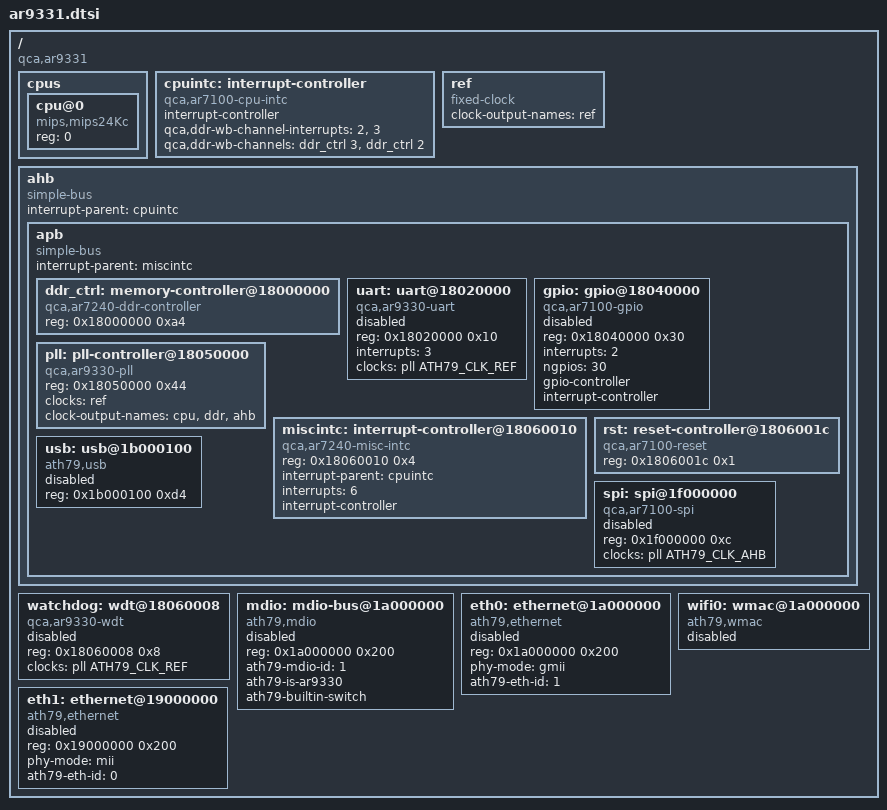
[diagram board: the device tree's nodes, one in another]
#include <dt-bindings/clock/ath79-clk.h>

/ {
	compatible = "qca,ar9331";

	#address-cells = <1>;
	#size-cells = <1>;

	cpus {
		#address-cells = <1>;
		#size-cells = <0>;

		cpu@0 {
			device_type = "cpu";
			compatible = "mips,mips24Kc";
			reg = <0>;
		};
	};

	cpuintc: interrupt-controller {
		compatible = "qca,ar7100-cpu-intc";

		interrupt-controller;
		#interrupt-cells = <1>;

		qca,ddr-wb-channel-interrupts = <2>, <3>;
		qca,ddr-wb-channels = <&ddr_ctrl 3>, <&ddr_ctrl 2>;
	};

	ref: ref {
		compatible = "fixed-clock";
		#clock-cells = <0>;
		clock-output-names = "ref";
	};

	ahb {
		compatible = "simple-bus";
		ranges;

		#address-cells = <1>;
		#size-cells = <1>;

		interrupt-parent = <&cpuintc>;

		apb {
			compatible = "simple-bus";
			ranges;

			#address-cells = <1>;
			#size-cells = <1>;

			interrupt-parent = <&miscintc>;

			ddr_ctrl: memory-controller@18000000 {
				compatible = "qca,ar7240-ddr-controller";
				reg = <0x18000000 0xa4>;

				#qca,ddr-wb-channel-cells = <1>;
			};

			uart: uart@18020000 {
				compatible = "qca,ar9330-uart";
				reg = <0x18020000 0x10>;

				interrupts = <3>;

				clocks = <&pll ATH79_CLK_REF>;
				clock-names = "uart";

				status = "disabled";
			};

			gpio: gpio@18040000 {
				compatible = "qca,ar7100-gpio";
				reg = <0x18040000 0x30>;
				interrupts = <2>;

				ngpios = <30>;

				gpio-controller;
				#gpio-cells = <2>;

				interrupt-controller;
				#interrupt-cells = <2>;

				status = "disabled";
			};

			pll: pll-controller@18050000 {
				compatible = "qca,ar9330-pll";
				reg = <0x18050000 0x44>;

				clocks = <&ref>;
				clock-names = "ref";

				#clock-cells = <1>;
				clock-output-names = "cpu", "ddr", "ahb";
			};

			miscintc: interrupt-controller@18060010 {
				compatible = "qca,ar7240-misc-intc";
				reg = <0x18060010 0x4>;

				interrupt-parent = <&cpuintc>;
				interrupts = <6>;

				interrupt-controller;
				#interrupt-cells = <1>;
			};

			rst: reset-controller@1806001c {
				compatible = "qca,ar7100-reset";
				reg = <0x1806001c 0x1>;

				#reset-cells = <1>;
			};

			usb: usb@1b000100 {
			/*	compatible = "qca,ar7100-ehci", "generic-ehci";
				reg = <0x1b000100 0xd4>;

				interrupt-parent = <&cpuintc>;
				interrupts = <3>;
				resets = <&rst 5>;

				has-transaction-translator;

				phy-names = "usb";
				phys = <&usb_phy>;*/

				compatible = "ath79,usb";
				reg = <0x1b000100 0xd4>;

				status = "disabled";
			};

			spi: spi@1f000000 {
				compatible = "qca,ar7100-spi";
				reg = <0x1f000000 0xc>;

				clocks = <&pll ATH79_CLK_AHB>;
				clock-names = "ahb";

				#address-cells = <1>;
				#size-cells = <0>;

				status = "disabled";
			};
		};
	};

	watchdog: wdt@18060008 {
		status = "disabled";

		compatible = "qca,ar9330-wdt", "qca,ar7130-wdt";
		reg = <0x18060008 0x8>;

		clocks = <&pll ATH79_CLK_REF>;
		clock-names = "wdt";
	};

	mdio: mdio-bus@1a000000 {
		status = "disabled";
		compatible = "ath79,mdio";
		reg = <0x1a000000 0x200>;

		ath79-mdio-id = <1>;

		ath79-is-ar9330;
		ath79-builtin-switch;

		#address-cells = <1>;
		#size-cells = <0>;
	};

	eth0: ethernet@1a000000 {
		status = "disabled";
		compatible = "ath79,ethernet";
		reg = <0x1a000000 0x200>;

		phy-mode = "gmii";

		ath79-eth-id = <1>;
	};

	eth1: ethernet@19000000 {
		status = "disabled";
		compatible = "ath79,ethernet";
		reg = <0x19000000 0x200>;

		phy-mode = "mii";

		ath79-eth-id = <0>;
	};

	wifi0: wmac@1a000000 {
		status = "disabled";
		compatible = "ath79,wmac";
	};

/*	usb_phy: usb-phy {
		compatible = "qca,ar7100-usb-phy";

		reset-names = "usb-phy", "usb-suspend-override";
		resets = <&rst 4>, <&rst 3>;

		#phy-cells = <0>;

		status = "disabled";
	};*/
};
